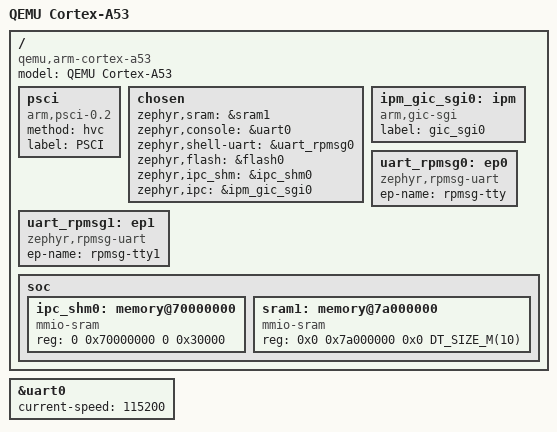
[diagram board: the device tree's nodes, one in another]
/*
 * Copyright (c) 2019 Carlo Caione <ccaione@baylibre.com>
 *
 * SPDX-License-Identifier: Apache-2.0
 *
 */

/dts-v1/;
#include <arm64/qemu/qemu-virt-a53.dtsi>

/ {
	model = "QEMU Cortex-A53";
	compatible = "qemu,arm-cortex-a53";

	psci {
		compatible = "arm,psci-0.2";
		method = "hvc";
		label = "PSCI";
	};

	chosen {
		zephyr,sram = &sram1;
		/* uart0 is used for debug, which also may be used by Linux */
		zephyr,console = &uart0;
		zephyr,shell-uart = &uart_rpmsg0;
		zephyr,flash = &flash0;
		/*
		 * shared memory reserved for the inter-processor communication
		 */
		 zephyr,ipc_shm = &ipc_shm0;
		 zephyr,ipc = &ipm_gic_sgi0;
	};

	ipm_gic_sgi0: ipm{
		compatible = "arm,gic-sgi";
		label = "gic_sgi0";
	};

	uart_rpmsg0: ep0 {
		status = "okay";
		compatible = "zephyr,rpmsg-uart";
		/* the rpmsg-tty driver requires ep-name should be rpmsg-tty* */
		ep-name = "rpmsg-tty";
	};

	uart_rpmsg1: ep1 {
		status = "okay";
		compatible = "zephyr,rpmsg-uart";
		ep-name = "rpmsg-tty1";
	};

	soc {

		ipc_shm0: memory@70000000 {
			compatible = "mmio-sram";
			reg = <0 0x70000000 0 0x30000>;
		};

		sram1: memory@7a000000 {
			compatible = "mmio-sram";
			reg = <0x0 0x7a000000 0x0 DT_SIZE_M(10)>;
		};

	};
};

&uart0 {
	status = "okay";
	current-speed = <115200>;
};
